# LM3S615 register map
File version: 7944
Registers are 32-bit, read-write, no defined reset value unless marked. A register's access mark holds for its fields unless they carry their own. Offsets are from the block's base; [hi:lo] are bit positions; {n}, {i} and the like mark numbered series.

## I2C0 — Register map for I2C0 peripheral
Base 0x40020000; register names take the prefix I2C0
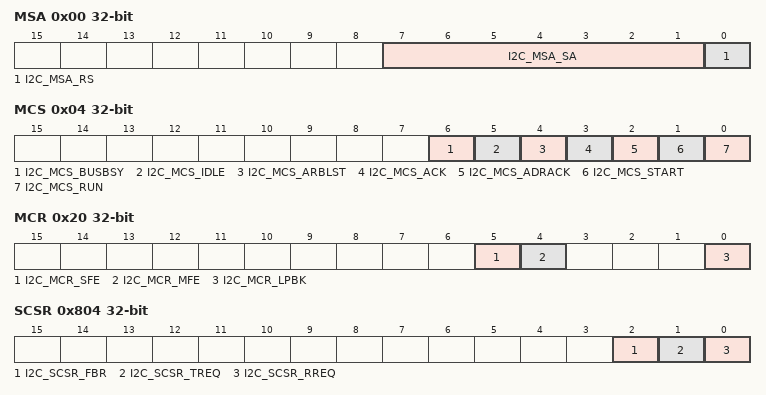
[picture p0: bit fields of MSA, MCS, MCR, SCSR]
0x00 MSA — I2C Master Slave Address
  [7:1] I2C_MSA_SA — I2C Slave Address
  [0] I2C_MSA_RS — Receive not send
0x04 MCS — I2C Master Control/Status
  [6] I2C_MCS_BUSBSY — Bus Busy
  [5] I2C_MCS_IDLE — I2C Idle
  [4] I2C_MCS_ARBLST — Arbitration Lost
  [3] I2C_MCS_ACK — Data Acknowledge Enable
  [2] I2C_MCS_ADRACK — Acknowledge Address
  [1] I2C_MCS_START — Generate START
  [0] I2C_MCS_RUN — I2C Master Enable
0x04 MCS (I2C0_ALT view) — I2C Master Control/Status
  [3] I2C_MCS_DATACK — Acknowledge Data
  [2] I2C_MCS_STOP — Generate STOP
  [1] I2C_MCS_ERROR — Error
  [0] I2C_MCS_BUSY — I2C Busy
0x08 MDR — I2C Master Data
  [7:0] I2C_MDR_DATA — Data Transferred
0x0C MTPR — I2C Master Timer Period
  [6:0] I2C_MTPR_TPR — SCL Clock Period
0x10 MIMR — I2C Master Interrupt Mask
  [0] I2C_MIMR_IM — Interrupt Mask
0x14 MRIS — I2C Master Raw Interrupt Status
  [0] I2C_MRIS_RIS — Raw Interrupt Status
0x18 MMIS — I2C Master Masked Interrupt Status
  [0] I2C_MMIS_MIS — Masked Interrupt Status
0x1C MICR wo — I2C Master Interrupt Clear
  [0] I2C_MICR_IC — Interrupt Clear
0x20 MCR — I2C Master Configuration
  [5] I2C_MCR_SFE — I2C Slave Function Enable
  [4] I2C_MCR_MFE — I2C Master Function Enable
  [0] I2C_MCR_LPBK — I2C Loopback
0x800 SOAR — I2C Slave Own Address
  [6:0] I2C_SOAR_OAR
0x804 SCSR — I2C Slave Control/Status
  [2] I2C_SCSR_FBR — First Byte Received
  [1] I2C_SCSR_TREQ — Transmit Request
  [0] I2C_SCSR_RREQ — Receive Request
0x804 SCSR (I2C0_ALT view) — I2C Slave Control/Status
  [0] I2C_SCSR_DA — Device Active
0x808 SDR — I2C Slave Data
  [7:0] I2C_SDR_DATA — Data for Transfer
0x80C SIMR — I2C Slave Interrupt Mask
  [0] I2C_SIMR_DATAIM — Data Interrupt Mask
0x810 SRIS — I2C Slave Raw Interrupt Status
  [0] I2C_SRIS_DATARIS — Data Raw Interrupt Status
0x814 SMIS — I2C Slave Masked Interrupt Status
  [0] I2C_SMIS_DATAMIS — Data Masked Interrupt Status
0x818 SICR wo — I2C Slave Interrupt Clear
  [0] I2C_SICR_DATAIC — Data Interrupt Clear

## COMP — Register map for COMP peripheral
Base 0x4003C000; register names take the prefix COMP
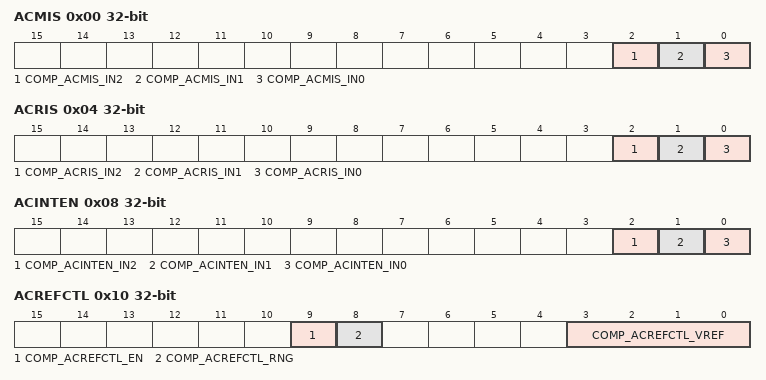
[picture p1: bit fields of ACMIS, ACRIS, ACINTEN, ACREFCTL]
0x00 ACMIS — Analog Comparator Masked Interrupt Status
  [2] COMP_ACMIS_IN2 — Comparator 2 Masked Interrupt Status
  [1] COMP_ACMIS_IN1 — Comparator 1 Masked Interrupt Status
  [0] COMP_ACMIS_IN0 — Comparator 0 Masked Interrupt Status
0x04 ACRIS — Analog Comparator Raw Interrupt Status
  [2] COMP_ACRIS_IN2 — Comparator 2 Interrupt Status
  [1] COMP_ACRIS_IN1 — Comparator 1 Interrupt Status
  [0] COMP_ACRIS_IN0 — Comparator 0 Interrupt Status
0x08 ACINTEN — Analog Comparator Interrupt Enable
  [2] COMP_ACINTEN_IN2 — Comparator 2 Interrupt Enable
  [1] COMP_ACINTEN_IN1 — Comparator 1 Interrupt Enable
  [0] COMP_ACINTEN_IN0 — Comparator 0 Interrupt Enable
0x10 ACREFCTL — Analog Comparator Reference Voltage Control
  [9] COMP_ACREFCTL_EN — Resistor Ladder Enable
  [8] COMP_ACREFCTL_RNG — Resistor Ladder Range
  [3:0] COMP_ACREFCTL_VREF — Resistor Ladder Voltage Ref
{0x20+0x20*i} ACSTAT{i} (i=0..2) — Analog Comparator Status {i}
  [1] COMP_ACSTAT{i}_OVAL — Comparator Output Value
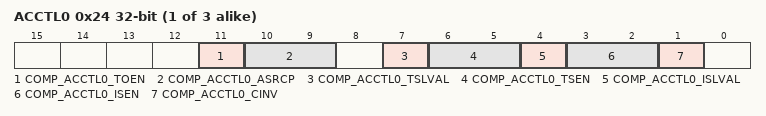
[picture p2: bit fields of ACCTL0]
{0x24+0x20*i} ACCTL{i} (i=0..2) — Analog Comparator Control {i}
  [11] COMP_ACCTL{i}_TOEN — Trigger Output Enable
  [10:9] COMP_ACCTL{i}_ASRCP — Analog Source Positive
    0=COMP_ACCTL{i}_ASRCP_PIN (Pin value of Cn+); 1=COMP_ACCTL{i}_ASRCP_PIN0 (Pin value of C0+); 2=COMP_ACCTL{i}_ASRCP_REF (Internal voltage reference (VIREF))
  [7] COMP_ACCTL{i}_TSLVAL — Trigger Sense Level Value
  [6:5] COMP_ACCTL{i}_TSEN — Trigger Sense
    0=COMP_ACCTL{i}_TSEN_LEVEL (Level sense, see TSLVAL); 1=COMP_ACCTL{i}_TSEN_FALL (Falling edge); 2=COMP_ACCTL{i}_TSEN_RISE (Rising edge); 3=COMP_ACCTL{i}_TSEN_BOTH (Either edge)
  [4] COMP_ACCTL{i}_ISLVAL — Interrupt Sense Level Value
  [3:2] COMP_ACCTL{i}_ISEN — Interrupt Sense
    0=COMP_ACCTL{i}_ISEN_LEVEL (Level sense, see ISLVAL); 1=COMP_ACCTL{i}_ISEN_FALL (Falling edge); 2=COMP_ACCTL{i}_ISEN_RISE (Rising edge); 3=COMP_ACCTL{i}_ISEN_BOTH (Either edge)
  [1] COMP_ACCTL{i}_CINV — Comparator Output Invert

## FLASH_CTRL — Register map for FLASH_CTRL peripheral
Base 0x400FD000; register names take the prefix FLASH_CTRL
0x00 FMA — Flash Memory Address
  [14:0] FLASH_FMA_OFFSET — Address Offset
0x04 FMD — Flash Memory Data
  [31:0] FLASH_FMD_DATA — Data Value
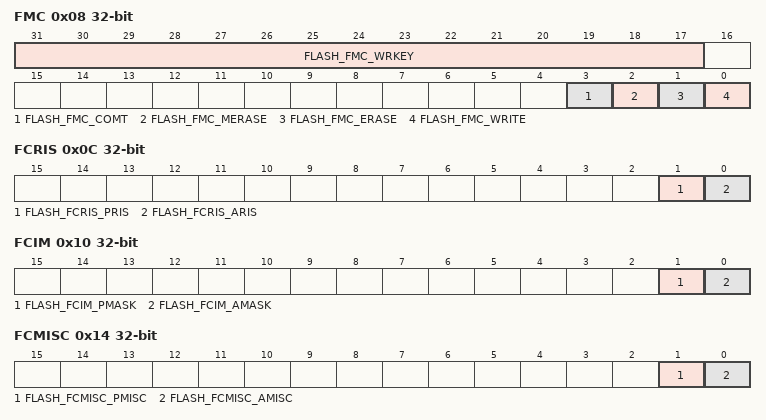
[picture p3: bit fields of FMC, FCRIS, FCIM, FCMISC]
0x08 FMC — Flash Memory Control
  [31:17] FLASH_FMC_WRKEY — FLASH write key
  [3] FLASH_FMC_COMT — Commit Register Value
  [2] FLASH_FMC_MERASE — Mass Erase Flash Memory
  [1] FLASH_FMC_ERASE — Erase a Page of Flash Memory
  [0] FLASH_FMC_WRITE — Write a Word into Flash Memory
0x0C FCRIS — Flash Controller Raw Interrupt Status
  [1] FLASH_FCRIS_PRIS — Programming Raw Interrupt Status
  [0] FLASH_FCRIS_ARIS — Access Raw Interrupt Status
0x10 FCIM — Flash Controller Interrupt Mask
  [1] FLASH_FCIM_PMASK — Programming Interrupt Mask
  [0] FLASH_FCIM_AMASK — Access Interrupt Mask
0x14 FCMISC — Flash Controller Masked Interrupt Status and Clear
  [1] FLASH_FCMISC_PMISC — Programming Masked Interrupt Status and Clear
  [0] FLASH_FCMISC_AMISC — Access Masked Interrupt Status and Clear
0x1130 FMPRE — Flash Memory Protection Read Enable
0x1134 FMPPE — Flash Memory Protection Program Enable
0x1140 USECRL — USec Reload
  [7:0] FLASH_USECRL — Microsecond Reload Value
